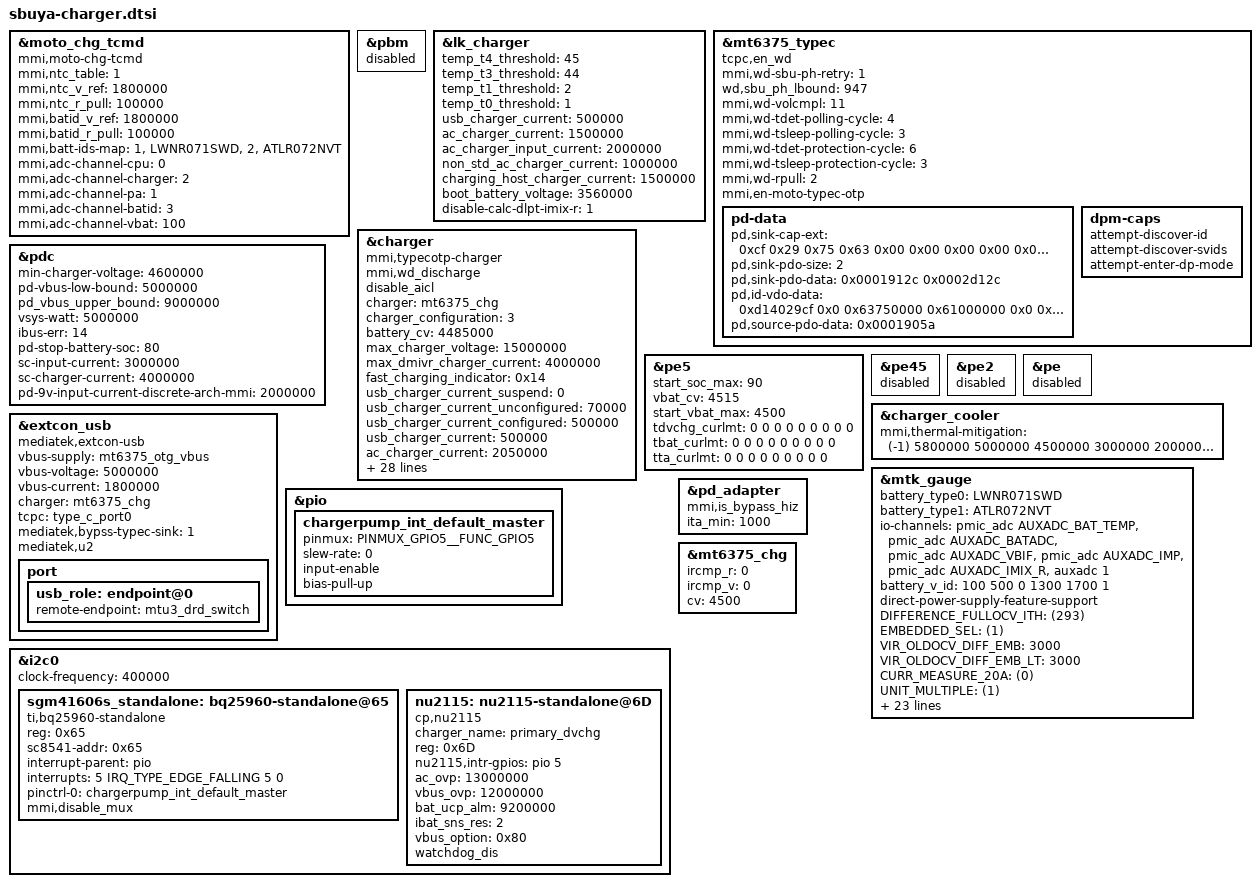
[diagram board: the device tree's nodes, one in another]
/*
 * Copyright (c) 2019 MediaTek Inc.
 *
 * This program is free software; you can redistribute it and/or modify
 * it under the terms of the GNU General Public License version 2 as
 * published by the Free Software Foundation.
 *
 * This program is distributed in the hope that it will be useful,
 * but WITHOUT ANY WARRANTY; without even the implied warranty of
 * MERCHANTABILITY or FITNESS FOR A PARTICULAR PURPOSE.  See the
 * GNU General Public License for more details.
 */
#include <dt-bindings/iio/adc/mediatek,mt6375_auxadc.h>
#include <dt-bindings/iio/adc/mediatek,mt6375_adc.h>
#include <dt-bindings/iio/mt635x-auxadc.h>

&moto_chg_tcmd {
                compatible = "mmi,moto-chg-tcmd";
                status = "okay";

                mmi,ntc_table = <1>;
                mmi,ntc_v_ref = <1800000>;
                mmi,ntc_r_pull = <100000>;

                mmi,batid_v_ref = <1800000>;
                mmi,batid_r_pull = <100000>;
                mmi,batt-ids-map = "1", "LWNR071SWD", "2", "ATLR072NVT";

                mmi,adc-channel-cpu = <0>;
                mmi,adc-channel-charger = <2>;
                mmi,adc-channel-pa = <1>;
                mmi,adc-channel-batid = <3>;
                mmi,adc-channel-vbat = <100>;
};

&pbm {
        status = "disabled";
};

&lk_charger {
		temp_t4_threshold = <45>;
		temp_t3_threshold = <44>;
		temp_t1_threshold = <2>;
		temp_t0_threshold = <1>;
        /* charging current */
        usb_charger_current = <500000>;
        ac_charger_current = <1500000>;
        ac_charger_input_current = <2000000>;
        non_std_ac_charger_current = <1000000>;
        charging_host_charger_current = <1500000>;
        boot_battery_voltage = <3560000>;
        disable-calc-dlpt-imix-r= <1>;
};

&mt6375_typec {
        tcpc,en_wd;

        mmi,wd-sbu-ph-retry = <1>;	/* 1 time */

        /*fcnt lpd configure*/
        wd,sbu_ph_lbound = <947>;	/*sbu to gnd 1250K*/

        /*SBU pin isr trigger voltage: lpd enter isr if < mmi-volcmpl. lpd isr eixt isr if > mmi-volcmpl */
        mmi,wd-volcmpl = <11>;		/* 1540mv */

        /*lpd polling periods: wd-tdet-polling-cycle * mmi,wd-tsleep-polling-cycle lpd */
        mmi,wd-tdet-polling-cycle = <4>;	/* 10ms*/
        mmi,wd-tsleep-polling-cycle = <3>;	/* 1024x*/

        /*lpd protection periods:  mmi,wd-tdet-polling-cycle*  mmi,wd-tsleep-protection-cycle lpd */
        mmi,wd-tdet-protection-cycle = <6>;	/* 100ms*/
        mmi,wd-tsleep-protection-cycle = <3>;	/* 1024x*/

        /*mmi,wd-rpull volcmpl pull up r */
        mmi,wd-rpull = <2>;	/* 75K */
        mmi,en-moto-typec-otp;
        pd-data {
                pd,sink-cap-ext = /bits/ 8 <0xcf 0x29 0x75 0x63
                                                0x00 0x00 0x00 0x00
                                                0x00 0x00 0x01 0x00
                                                0x00 0x00 0x00 0x00
                                                0x01 0x0b 0x01 0x0a
                                                0x1b 0x00 0x00 0x00>;
                /*5V, 3A  9V, 3A*/
                pd,sink-pdo-size = <2>;
                pd,sink-pdo-data = <0x0001912c 0x0002d12c> ;
                pd,id-vdo-data = <0xd14029cf 0x0 0x63750000
                                0x61000000 0x0 0x41000000>;
		/* 5V, 900ma */
                pd,source-pdo-data = <0x0001905a>;
        };

        dpm-caps {
                attempt-discover-id;
                attempt-discover-svids;
                attempt-enter-dp-mode;
        };
};

&charger {
         mmi,typecotp-charger;
         /* wd discharge */
         mmi,wd_discharge;
         /* disabled aicl */
         disable_aicl;
         charger = <&mt6375_chg>;
         charger_configuration= <3>;
         /* common */
         battery_cv = <4485000>;
         max_charger_voltage = <15000000>;
         max_dmivr_charger_current = <4000000>;
         //enable_pe_plus;
         //enable_sw_jeita;

         /*pe5 && pdc*/
         fast_charging_indicator = <0x14>;

         /* charging current */
         usb_charger_current_suspend = <0>;
         usb_charger_current_unconfigured = <70000>;
         usb_charger_current_configured = <500000>;
         usb_charger_current = <500000>;
         ac_charger_current = <2050000>;
         ac_charger_input_current = <2000000>;
         non_std_ac_charger_current = <1000000>;
         charging_host_charger_current = <1500000>;
         apple_1_0a_charger_current = <650000>;
         apple_2_1a_charger_current = <800000>;
         ta_ac_charger_current = <3600000>;
         typec_limit_aicr = <3000000>;

         /* PE */
         ta_ac_9v_input_current = <2000000>;
         ta_ac_7v_input_current = <2000000>;

         //mmi config
         mmi,iterm-ma = <243>;
         mmi,batt-max-temp = <45>;
         mmi,batt-min-temp = <0>;
         mmi,mmi-temp-zones = <10 4250 2435 1461>,
                        <15 0 2435 2435>,
                        <35 4320 6000 5200>,
                        <35 4450 5200 4000>,
                        <45 4320 6000 5200>,
                        <45 4450 5200 4000>;

         mmi,mmi-ffc-zones = <10 4485 255>,
                        <15 4485 255>,
                        <25 4515 739>,
                        <35 4515 893>,
                        <45 4515 1547>;

         mmi,mmi-normal-zones = <10 4485 255>,
                        <15 4485 255>,
                        <25 4485 255>,
                        <35 4485 255>,
                        <45 4485 487>;

         mmi,enable-charging-limit;
         mmi,upper-limit-capacity = <65>;
         mmi,lower-limit-capacity = <60>;
         mmi,vfloat-comp-uv = <0>;
         mmi,min-cp-therm-current-ua = <1000000>;
         mmi,power-max-design-mw = <30000>;
         /*CONFIG_MOTO_1200_CYCLE*/
         mmi,mmi-cycle-cv-steps =<100 5>;
};

&pdc {
         min-charger-voltage = <4600000>;
         pd-vbus-low-bound = <5000000>;
         pd_vbus_upper_bound = <9000000>;
         vsys-watt = <5000000>;
         ibus-err = <14>;

         pd-stop-battery-soc = <80>;

         /* single charger */
         sc-input-current = <3000000>;
         sc-charger-current = <4000000>;
         pd-9v-input-current-discrete-arch-mmi = <2000000>;
};

&pe5 {
	start_soc_max = <90>;
	vbat_cv = <4515>;
	start_vbat_max = <4500>;

	/* Sbuya disable temperature current limit */
	tdvchg_curlmt = <0 0 0 0 0 0 0 0 0>;
	tbat_curlmt = <0 0 0 0 0 0 0 0 0>;
	tta_curlmt = <0 0 0 0 0 0 0 0 0>;
};

&pe45 {
	status = "disabled";
};

&pe2 {
	status = "disabled";
};

&pe {
	status = "disabled";
};

&charger_cooler {
       mmi,thermal-mitigation = <(-1) 5800000 5000000 4500000 3000000
                               2000000 1500000 1000000 500000>;
};

&extcon_usb {
	compatible = "mediatek,extcon-usb";
	vbus-supply = <&mt6375_otg_vbus>;
	vbus-voltage = <5000000>;
	vbus-current = <1800000>;
	charger = <&mt6375_chg>;
	tcpc = "type_c_port0";
	mediatek,bypss-typec-sink = <1>;
	mediatek,u2;
	port {
		usb_role: endpoint@0 {
			remote-endpoint = <&mtu3_drd_switch>;
		};
	};
};

&mtk_gauge {
	//fnct qns battery type
	battery_type0 = "LWNR071SWD";
	battery_type1 = "ATLR072NVT";
	io-channels = <&pmic_adc AUXADC_BAT_TEMP>,
			<&pmic_adc AUXADC_BATADC>,
			<&pmic_adc AUXADC_VBIF>,
			<&pmic_adc AUXADC_IMP>,
			<&pmic_adc AUXADC_IMIX_R>,
			<&auxadc 1>;  /* batteryid io-channels is mt6835 auxadc1 */
	io-channel-names = "pmic_battery_temp",
			"pmic_battery_voltage",
			"pmic_bif_voltage",
			"pmic_ptim_voltage",
			"pmic_ptim_r",
			"batteryID-channel";
	/* bat_id vmin_vmax_id */
	battery_v_id = <100 500 0
	1300 1700 1>;
	/*direct charge feature*/
	direct-power-supply-feature-support;
	DIFFERENCE_FULLOCV_ITH = <(293)>;  /*gauge cut-off current, should overtop ieoc 50ma*/
	EMBEDDED_SEL = <(1)>;  /*embedded battery,don't remove the battery for user*/
	VIR_OLDOCV_DIFF_EMB = <3000>; /*0.1mv*/
	VIR_OLDOCV_DIFF_EMB_LT = <3000>; /*0.1mv*/
	CURR_MEASURE_20A = <(0)>;
	UNIT_MULTIPLE = <(1)>;

	/* battery prop */
	g_temperature = <(50) (25) (10) (0) (-10) (-25) (-30) (-35) (-40) (-45)>;
	g_FG_PSEUDO100 = <97 97 97 97
		97 97 97 97
		97 97 97 97
		97 97 97 97
		97 97 97 97
		100 100 100 100
		100 100 100 100
		100 100 100 100
		100 100 100 100
		100 100 100 100>;

	g_Q_MAX = <4952 5044 4952 4952
		5034 5050 5034 5034
		4954 5105 4954 4954
		4880 4811 4880 4880
		4712 4712 4712 4712
		4990 4996 4996 4996
		4990 4996 4996 4996
		4990 4996 4996 4996
		4990 4996 4996 4996
		4990 4996 4996 4996>;

	g_Q_MAX_H_CURRENT = <4935 5018 4935 4935
		5016 5037 5016 5016
		4866 5101 4866 4866
		4673 4912 4673 4673
		4297 4297 4297 4297
		4970 4805 4990 4990
		4970 4990 4990 4990
		4970 4990 4990 4990
		4970 4990 4990 4990
		4970 4990 4990 4990>;

	/*vboot voltage for gauge 0%*/
	g_PMIC_MIN_VOL_row = <4>;
	g_PMIC_MIN_VOL_col = <10>;
	g_PMIC_MIN_VOL = <31840  32930  31840  31840
		33080  30880  33080  33080
		33220  31970  33220  33220
		33350  35040  33350  33350
		33350  35940  33350  33350
		31500  31500  31500  31500
		31000  31000  31000  31000
		31000  31000  31000  31000
		31000  31000  31000  31000
		31000  31000  31000  31200>;

	/*Pseudo1 hide percentage*/
	g_QMAX_SYS_VOL_row = <4>;
	g_QMAX_SYS_VOL_col = <10>;
	g_QMAX_SYS_VOL = <32340  33430  32340  32340
		33580  31380  33580  33580
		33720  32470  33720  33720
		34000  35540  34000  34000
		34000  36440  34000  34000
		32500  32500  32500  32500
		32800  32800  32800  32800
		32800  32800  32800  32800
		32800  32800  32800  32800
		32800  32800  32800  32800>;

	SHUTDOWN_1_TIME = <(30)>;
	TEMPERATURE_T4 = <(-10)>;
	ACTIVE_TABLE = <(5)>;
	R_FG_VALUE = <(2)>;
	NO_BAT_TEMP_COMPENSATE = <(1)>;
	CAR_TUNE_VALUE = <(99)>;

	df-serialnum = "LWNR071SWD";
	#include "bat_setting/mt6835_battery_sbuya_swd_5000mah.dtsi"
	#include "bat_setting/mt6835_battery_sbuya_nvt_5000mah.dtsi"
};

&pio {
     chargerpump_int_default_master: chargerpump_int_default_master {
		pinmux = <PINMUX_GPIO5__FUNC_GPIO5>;
		slew-rate= <0>;
		input-enable;
		bias-pull-up;
     };
};

&i2c0 {
	clock-frequency = <400000>;
	sgm41606s_standalone:bq25960-standalone@65 {
		status = "okay";
		compatible = "ti,bq25960-standalone";
		reg = <0x65>;

		sc8541-addr = <0x65>;

		interrupt-parent = <&pio>;
		interrupts = <5 IRQ_TYPE_EDGE_FALLING 5 0>;
		interrupt-names = "bq25960_irq_standalone";

		pinctrl-names = "default";
		pinctrl-0 = <&chargerpump_int_default_master>;

		/* Sbuya disable otg mux */
		mmi,disable_mux;
	};
	nu2115: nu2115-standalone@6D {
		compatible = "cp,nu2115";
		status = "okay";
		charger_name = "primary_dvchg";
		reg = <0x6D>;
		nu2115,intr-gpios = <&pio 5 0x0>;
		ac_ovp = <13000000>;
		vbus_ovp = <12000000>;
		bat_ucp_alm = <9200000>;
		ibat_sns_res = <2>;
		vbus_option = <0x80>;
		watchdog_dis;
	};
};
&pd_adapter {
	mmi,is_bypass_hiz;
};

&pd_adapter {
		ita_min = <1000>;
};

&mt6375_chg {
		ircmp_r = <0>;
		ircmp_v = <0>;
		cv = <4500>;
};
